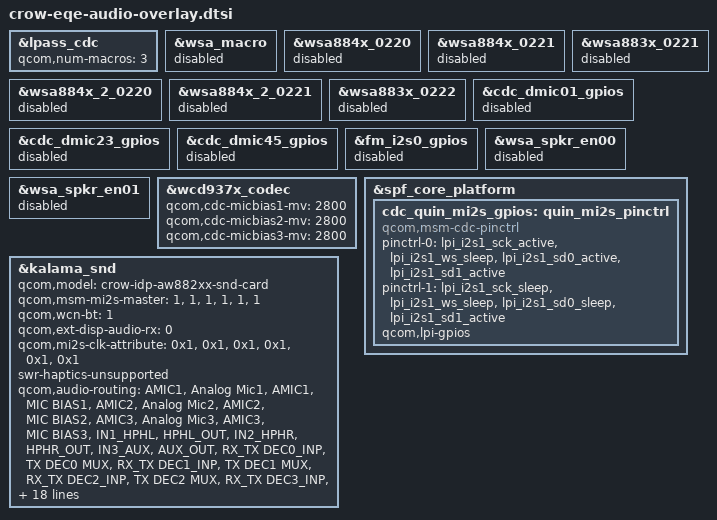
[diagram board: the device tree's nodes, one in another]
&lpass_cdc {
        qcom,num-macros = <3>;
};

&wsa_macro {
        status = "disabled";
};

&wsa884x_0220 {
        status = "disabled";
};

&wsa884x_0221 {
        status = "disabled";
};

&wsa884x_2_0220 {
        status = "disabled";
};

&wsa884x_2_0221 {
        status = "disabled";
};

&wsa883x_0221 {
        status = "disabled";
};

&wsa883x_0222 {
        status = "disabled";
};

&cdc_dmic01_gpios {
        status = "disabled";
};

&cdc_dmic23_gpios {
        status = "disabled";
};

&cdc_dmic45_gpios {
        status = "disabled";
};

&fm_i2s0_gpios {
        status = "disabled";
};

&wsa_spkr_en00 {
        status = "disabled";
};

&wsa_spkr_en01 {
        status = "disabled";
};

&wcd937x_codec {
        status = "okay";
        qcom,cdc-micbias1-mv = <2800>;
        qcom,cdc-micbias2-mv = <2800>;
        qcom,cdc-micbias3-mv = <2800>;
};

&spf_core_platform {
        cdc_quin_mi2s_gpios:  quin_mi2s_pinctrl {
                compatible = "qcom,msm-cdc-pinctrl";
                pinctrl-names = "aud_active","aud_sleep";
                pinctrl-0 = <&lpi_i2s1_sck_active &lpi_i2s1_ws_sleep
                                &lpi_i2s1_sd0_active &lpi_i2s1_sd1_active>;
                pinctrl-1 = <&lpi_i2s1_sck_sleep &lpi_i2s1_ws_sleep
                                &lpi_i2s1_sd0_sleep &lpi_i2s1_sd1_active>;
                qcom,lpi-gpios;
                #gpio-cells = <0>;
        };
};


&kalama_snd {
        qcom,model = "crow-idp-aw882xx-snd-card";
        qcom,msm-mi2s-master = <1>, <1>, <1>, <1>, <1>, <1>;
        qcom,wcn-bt = <1>;
        qcom,ext-disp-audio-rx = <0>;
        qcom,mi2s-clk-attribute = <0x1>, <0x1>, <0x1>, <0x1>, <0x1>, <0x1>;
        swr-haptics-unsupported;
        qcom,audio-routing =
                "AMIC1", "Analog Mic1",
                "AMIC1", "MIC BIAS1",
                "AMIC2", "Analog Mic2",
                "AMIC2", "MIC BIAS2",
                "AMIC3", "Analog Mic3",
                "AMIC3", "MIC BIAS3",
                "IN1_HPHL", "HPHL_OUT",
                "IN2_HPHR", "HPHR_OUT",
                "IN3_AUX", "AUX_OUT",
                "RX_TX DEC0_INP", "TX DEC0 MUX",
                "RX_TX DEC1_INP", "TX DEC1 MUX",
                "RX_TX DEC2_INP", "TX DEC2 MUX",
                "RX_TX DEC3_INP", "TX DEC3 MUX",
                "TX SWR_INPUT", "WCD_TX_OUTPUT",
                "VA SWR_INPUT", "VA_SWR_CLK",
                "VA SWR_INPUT", "WCD_TX_OUTPUT",
                "VA_AIF1 CAP", "VA_SWR_CLK",
                "VA_AIF2 CAP", "VA_SWR_CLK",
                "VA_AIF3 CAP", "VA_SWR_CLK";
        qcom,msm-mbhc-usbc-audio-supported = <1>;
        qcom,msm-mbhc-hphl-swh = <0>;
        qcom,msm-mbhc-gnd-swh = <0>;
        qcom,mi2s-audio-intf = <1>;
        qcom,quin-mi2s-gpios = <&cdc_quin_mi2s_gpios>;
        fsa4480-i2c-handle = <&fsa4480>;

        /delete-property/ qcom,cdc-dmic01-gpios;
        /delete-property/ qcom,cdc-dmic23-gpios;
        /delete-property/ qcom,cdc-dmic45-gpios;

        asoc-codec  = <&stub_codec>, <&lpass_cdc>,
                      <&wcd937x_codec>,
                      <&aw882xxacf_spk>, <&aw882xxacf_rcv>;
        asoc-codec-names = "msm-stub-codec.1", "lpass-cdc",
                      "wcd937x_codec",
                      "aw882xx_smartpa.1-0035", "aw882xx_smartpa.1-0034";
        qcom,wsa-max-devs = <0>;
};
